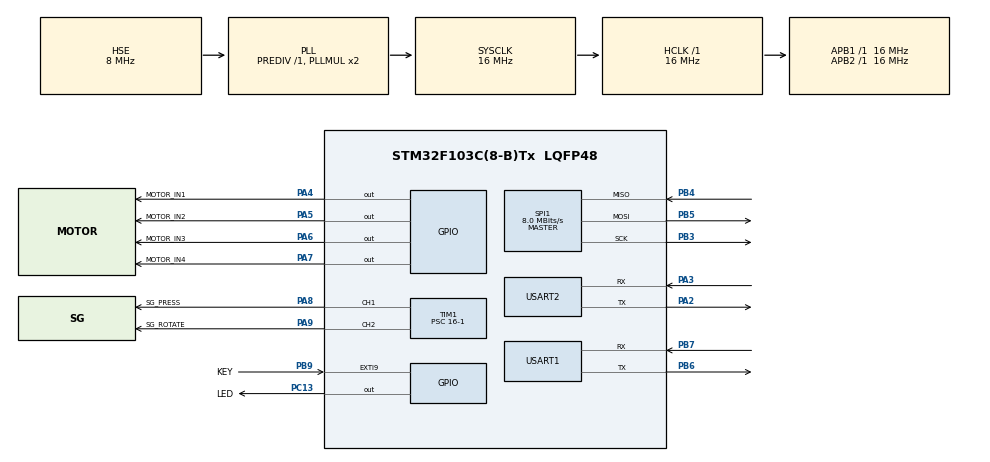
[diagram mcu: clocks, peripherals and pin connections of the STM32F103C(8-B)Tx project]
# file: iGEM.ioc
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Dma.Request0=SPI1_TX
Dma.SPI1_TX.0.Direction=DMA_MEMORY_TO_PERIPH
Dma.SPI1_TX.0.Instance=DMA1_Channel3
Dma.SPI1_TX.0.MemDataAlignment=DMA_MDATAALIGN_BYTE
Dma.SPI1_TX.0.MemInc=DMA_MINC_ENABLE
Dma.SPI1_TX.0.Mode=DMA_NORMAL
Dma.SPI1_TX.0.PeriphDataAlignment=DMA_PDATAALIGN_BYTE
Dma.SPI1_TX.0.PeriphInc=DMA_PINC_DISABLE
Dma.SPI1_TX.0.Priority=DMA_PRIORITY_VERY_HIGH
FREERTOS.INCLUDE_eTaskGetState=1
FREERTOS.INCLUDE_pcTaskGetTaskName=1
FREERTOS.INCLUDE_uxTaskGetStackHighWaterMark=1
FREERTOS.INCLUDE_vTaskCleanUpResources=1
FREERTOS.INCLUDE_vTaskDelayUntil=1
FREERTOS.INCLUDE_xQueueGetMutexHolder=1
FREERTOS.INCLUDE_xSemaphoreGetMutexHolder=1
FREERTOS.INCLUDE_xTaskAbortDelay=1
FREERTOS.INCLUDE_xTaskGetCurrentTaskHandle=1
FREERTOS.INCLUDE_xTaskGetHandle=1
FREERTOS.Tasks01=defaultTask,-1,128,StartDefaultTask,As weak,NULL,Dynamic,NULL,NULL;controlTask,2,128,ControlTaskFunction,As weak,NULL,Dynamic,NULL,NULL
Mcu.Family=STM32F1
Mcu.Name=STM32F103C(8-B)Tx
Mcu.Package=LQFP48
NVIC.DMA1_Channel3_IRQn=true\:5\:0\:false\:false\:true\:true\:false\:true\:true
NVIC.EXTI9_5_IRQn=true\:7\:0\:true\:false\:true\:true\:true\:true\:true
NVIC.PriorityGroup=NVIC_PRIORITYGROUP_4
NVIC.TIM2_IRQn=true\:15\:0\:false\:false\:true\:false\:false\:true\:true
NVIC.TimeBase=TIM2_IRQn
NVIC.TimeBaseIP=TIM2
NVIC.USART1_IRQn=true\:5\:0\:false\:false\:true\:true\:true\:true\:true
NVIC.USART2_IRQn=true\:6\:0\:true\:false\:true\:true\:true\:true\:true
PA13.Mode=Serial_Wire
PA13.Signal=SYS_JTMS-SWDIO
PA14.Mode=Serial_Wire
PA14.Signal=SYS_JTCK-SWCLK
PA2.Mode=Asynchronous
PA2.Signal=USART2_TX
PA3.Mode=Asynchronous
PA3.Signal=USART2_RX
PA4.GPIO_Label=MOTOR_IN1
PA4.GPIO_PuPd=GPIO_PULLDOWN
PA4.GPIO_Speed=GPIO_SPEED_FREQ_HIGH
PA4.Signal=GPIO_Output
PA5.GPIO_Label=MOTOR_IN2
PA5.GPIO_PuPd=GPIO_PULLDOWN
PA5.GPIO_Speed=GPIO_SPEED_FREQ_HIGH
PA5.Signal=GPIO_Output
PA6.GPIO_Label=MOTOR_IN3
PA6.GPIO_PuPd=GPIO_PULLDOWN
PA6.GPIO_Speed=GPIO_SPEED_FREQ_HIGH
PA6.Signal=GPIO_Output
PA7.GPIO_Label=MOTOR_IN4
PA7.GPIO_PuPd=GPIO_PULLDOWN
PA7.GPIO_Speed=GPIO_SPEED_FREQ_HIGH
PA7.Signal=GPIO_Output
PA8.GPIO_Label=SG_PRESS
PA8.GPIO_Speed=GPIO_SPEED_FREQ_HIGH
PA8.Signal=S_TIM1_CH1
PA9.GPIO_Label=SG_ROTATE
PA9.GPIO_Speed=GPIO_SPEED_FREQ_HIGH
PA9.Signal=S_TIM1_CH2
PB3.Mode=Full_Duplex_Master
PB3.Signal=SPI1_SCK
PB4.Mode=Full_Duplex_Master
PB4.Signal=SPI1_MISO
PB5.Mode=Full_Duplex_Master
PB5.Signal=SPI1_MOSI
PB6.Mode=Asynchronous
PB6.Signal=USART1_TX
PB7.Mode=Asynchronous
PB7.Signal=USART1_RX
PB9.GPIO_Label=KEY
PB9.GPIO_ModeDefaultEXTI=GPIO_MODE_IT_FALLING
PB9.GPIO_PuPd=GPIO_PULLUP
PB9.Signal=GPXTI9
PC13-TAMPER-RTC.GPIO_Label=LED
PC13-TAMPER-RTC.GPIO_Speed=GPIO_SPEED_FREQ_MEDIUM
PC13-TAMPER-RTC.Signal=GPIO_Output
PD0-OSC_IN.Mode=HSE-External-Oscillator
PD0-OSC_IN.Signal=RCC_OSC_IN
PD1-OSC_OUT.Mode=HSE-External-Oscillator
PD1-OSC_OUT.Signal=RCC_OSC_OUT
ProjectManager.HeapSize=0x200
ProjectManager.StackSize=0x400
ProjectManager.TargetToolchain=MDK-ARM V5.32
RCC.AHBFreq_Value=16000000
RCC.APB1Freq_Value=16000000
RCC.APB1TimFreq_Value=16000000
RCC.APB2Freq_Value=16000000
RCC.APB2TimFreq_Value=16000000
RCC.HCLKFreq_Value=16000000
RCC.PLLSourceVirtual=RCC_PLLSOURCE_HSE
RCC.SYSCLKFreq_VALUE=16000000
RCC.SYSCLKSource=RCC_SYSCLKSOURCE_PLLCLK
RCC.USBFreq_Value=16000000
SH.S_TIM1_CH1.0=TIM1_CH1,PWM Generation1 CH1
SH.S_TIM1_CH2.0=TIM1_CH2,PWM Generation2 CH2
SPI1.BaudRatePrescaler=SPI_BAUDRATEPRESCALER_2
SPI1.CLKPhase=SPI_PHASE_2EDGE
SPI1.CLKPolarity=SPI_POLARITY_LOW
SPI1.CRCCalculation=SPI_CRCCALCULATION_DISABLE
SPI1.CalculateBaudRate=8.0 MBits/s
SPI1.Direction=SPI_DIRECTION_2LINES
SPI1.Mode=SPI_MODE_MASTER
SPI1.VirtualType=VM_MASTER
TIM1.Channel-PWM\ Generation1\ CH1=TIM_CHANNEL_1
TIM1.Channel-PWM\ Generation2\ CH2=TIM_CHANNEL_2
TIM1.Period=20000-1
TIM1.Prescaler=16-1
USART1.VirtualMode=VM_ASYNC
USART2.VirtualMode=VM_ASYNC
VP_FREERTOS_VS_CMSIS_V1.Mode=CMSIS_V1
VP_SYS_VS_tim2.Mode=TIM2
VP_TIM1_VS_ClockSourceINT.Mode=Internal
board=custom

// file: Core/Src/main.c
/* USER CODE BEGIN Header */
/**
  ******************************************************************************
  * @file           : main.c
  * @brief          : Main program body
  ******************************************************************************
  * @attention
  *
  * Copyright (c) 2022 STMicroelectronics.
  * All rights reserved.
  *
  * This software is licensed under terms that can be found in the LICENSE file
  * in the root directory of this software component.
  * If no LICENSE file comes with this software, it is provided AS-IS.
  *
  ******************************************************************************
  */
/* USER CODE END Header */
#include "main.h"
#include "cmsis_os.h"
#include "dma.h"
#include "spi.h"
#include "tim.h"
#include "usart.h"
#include "gpio.h"

/* USER CODE BEGIN Includes */
#include "control.h"

/* USER CODE END Includes */

void SystemClock_Config(void);
void MX_FREERTOS_Init(void);

int main(void)
{

  /* MCU Configuration--------------------------------------------------------*/

  /* Reset of all peripherals, Initializes the Flash interface and the Systick. */
  HAL_Init();

  /* Configure the system clock */
  SystemClock_Config();

  /* Initialize all configured peripherals */
  MX_GPIO_Init();
  MX_TIM1_Init();
  MX_DMA_Init();
  MX_USART2_UART_Init();
  MX_SPI1_Init();
  MX_USART1_UART_Init();
  /* USER CODE BEGIN 2 */
	__HAL_UART_ENABLE_IT(&huart1, UART_IT_RXNE); 	// receive interrupt
	__HAL_UART_ENABLE_IT(&huart2, UART_IT_RXNE); 	// receive interrupt
	HAL_UART_Receive_IT(&huart1, &receive_data, 1);
	HAL_UART_Receive_IT(&huart2, &receive_data, 1);
  /* USER CODE END 2 */

  /* Call init function for freertos objects (in freertos.c) */
  MX_FREERTOS_Init();

  /* Start scheduler */
  osKernelStart();

  /* We should never get here as control is now taken by the scheduler */
  /* Infinite loop */
  while (1)
  {

  }
}

void SystemClock_Config(void)
{
  RCC_OscInitTypeDef RCC_OscInitStruct = {0};
  RCC_ClkInitTypeDef RCC_ClkInitStruct = {0};

  /** Initializes the RCC Oscillators according to the specified parameters
  * in the RCC_OscInitTypeDef structure.
  */
  RCC_OscInitStruct.OscillatorType = RCC_OSCILLATORTYPE_HSE;
  RCC_OscInitStruct.HSEState = RCC_HSE_ON;
  RCC_OscInitStruct.HSEPredivValue = RCC_HSE_PREDIV_DIV1;
  RCC_OscInitStruct.HSIState = RCC_HSI_ON;
  RCC_OscInitStruct.PLL.PLLState = RCC_PLL_ON;
  RCC_OscInitStruct.PLL.PLLSource = RCC_PLLSOURCE_HSE;
  RCC_OscInitStruct.PLL.PLLMUL = RCC_PLL_MUL2;
  if (HAL_RCC_OscConfig(&RCC_OscInitStruct) != HAL_OK)
  {
    Error_Handler();
  }

  /** Initializes the CPU, AHB and APB buses clocks
  */
  RCC_ClkInitStruct.ClockType = RCC_CLOCKTYPE_HCLK|RCC_CLOCKTYPE_SYSCLK
                              |RCC_CLOCKTYPE_PCLK1|RCC_CLOCKTYPE_PCLK2;
  RCC_ClkInitStruct.SYSCLKSource = RCC_SYSCLKSOURCE_PLLCLK;
  RCC_ClkInitStruct.AHBCLKDivider = RCC_SYSCLK_DIV1;
  RCC_ClkInitStruct.APB1CLKDivider = RCC_HCLK_DIV1;
  RCC_ClkInitStruct.APB2CLKDivider = RCC_HCLK_DIV1;

  if (HAL_RCC_ClockConfig(&RCC_ClkInitStruct, FLASH_LATENCY_0) != HAL_OK)
  {
    Error_Handler();
  }
}

void HAL_TIM_PeriodElapsedCallback(TIM_HandleTypeDef *htim)
{
  if (htim->Instance == TIM2) {
    HAL_IncTick();
  }
}

void Error_Handler(void)
{
  __disable_irq();
  while (1)
  {
  }
}
